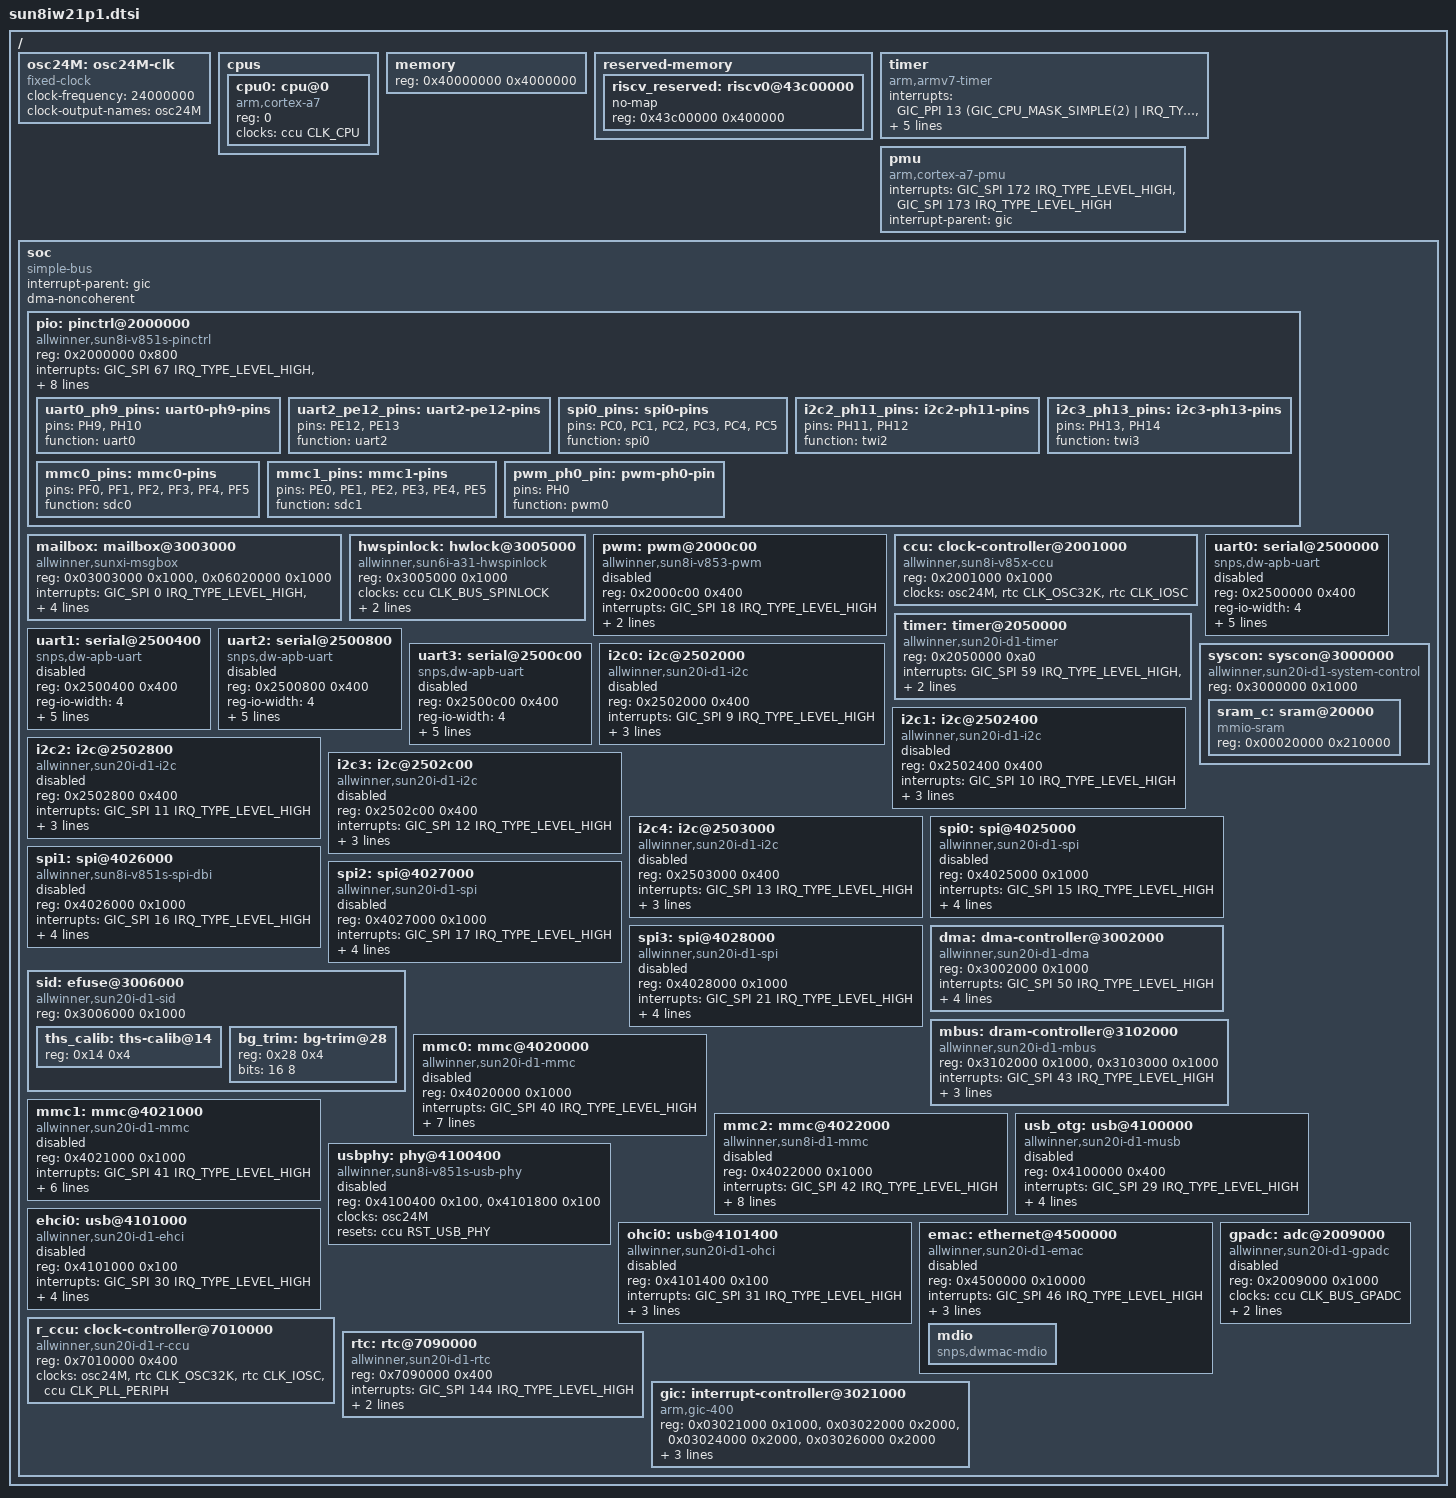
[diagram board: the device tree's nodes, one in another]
// SPDX-License-Identifier: (GPL-2.0+ or MIT)
// Copyright (C) 2021-2022 Samuel Holland <samuel@sholland.org>

#include <dt-bindings/clock/sun6i-rtc.h>
#include <dt-bindings/clock/sun8i-de2.h>
#include <dt-bindings/clock/sun8i-tcon-top.h>
#include <dt-bindings/clock/sun20i-d1-r-ccu.h>
#include <dt-bindings/reset/sun20i-d1-r-ccu.h>
#include <dt-bindings/clock/sun8i-v85x-ccu.h>
#include <dt-bindings/reset/sun8i-v85x-ccu.h>
#include <dt-bindings/interrupt-controller/arm-gic.h>
#include <dt-bindings/reset/sun8i-de2.h>
#include <dt-bindings/thermal/thermal.h>

/ {
	#address-cells = <1>;
	#size-cells = <1>;

	osc24M: osc24M-clk {
		compatible = "fixed-clock";
		clock-frequency = <24000000>;
		clock-output-names = "osc24M";
		#clock-cells = <0>;
	};

	cpus {
			#address-cells = <1>;
			#size-cells = <0>;

			cpu0: cpu@0 {
				device_type = "cpu";
				compatible = "arm,cortex-a7";
				reg = <0>;
				clocks = <&ccu CLK_CPU>;
				clock-names = "cpu";
			};
	};

	memory {
		reg = <0x40000000 0x4000000>;
	};

	reserved-memory {
		#address-cells = <1>;
		#size-cells = <1>;
		ranges;

		riscv_reserved: riscv0@43c00000 {
			no-map;
			reg = <0x43c00000 0x400000>;
		};
	};

	timer {
		compatible = "arm,armv7-timer";
		interrupts = <GIC_PPI 13 (GIC_CPU_MASK_SIMPLE(2) | IRQ_TYPE_LEVEL_LOW)>,
					 <GIC_PPI 14 (GIC_CPU_MASK_SIMPLE(2) | IRQ_TYPE_LEVEL_LOW)>,
					 <GIC_PPI 11 (GIC_CPU_MASK_SIMPLE(2) | IRQ_TYPE_LEVEL_LOW)>,
					 <GIC_PPI 10 (GIC_CPU_MASK_SIMPLE(2) | IRQ_TYPE_LEVEL_LOW)>;
		clock-frequency = <24000000>;
		interrupt-parent = <&gic>;
/*
		arm,cpu-registers-not-fw-configured;
		arm,no-tick-in-suspend;
*/
	};

	pmu {
		compatible = "arm,cortex-a7-pmu";
		interrupts = <GIC_SPI 172 IRQ_TYPE_LEVEL_HIGH>,
					 <GIC_SPI 173 IRQ_TYPE_LEVEL_HIGH>;
		interrupt-parent = <&gic>;
	};

	soc {
		compatible = "simple-bus";
		ranges;
		interrupt-parent = <&gic>;
		#address-cells = <1>;
		#size-cells = <1>;
		dma-noncoherent;

/* A (B) C D E F (G) H */

		pio: pinctrl@2000000 {
			compatible = "allwinner,sun8i-v851s-pinctrl";
			reg = <0x2000000 0x800>;
			interrupts = <GIC_SPI 67 IRQ_TYPE_LEVEL_HIGH>, /* GPIOA */
						 <GIC_SPI 71 IRQ_TYPE_LEVEL_HIGH>, /* GPIOC */
						 <GIC_SPI 73 IRQ_TYPE_LEVEL_HIGH>, /* GPIOD */
						 <GIC_SPI 75 IRQ_TYPE_LEVEL_HIGH>, /* GPIOE */
						 <GIC_SPI 77 IRQ_TYPE_LEVEL_HIGH>, /* GPIOF */
						 <GIC_SPI 81 IRQ_TYPE_LEVEL_HIGH>; /* GPIOH */
			clocks = <&ccu CLK_APB0>, <&osc24M>, <&rtc CLK_OSC32K>;
			clock-names = "apb", "hosc", "losc";
			gpio-controller;
			interrupt-controller;
			#gpio-cells = <3>;
			#interrupt-cells = <3>;

			/omit-if-no-ref/
			uart0_ph9_pins: uart0-ph9-pins {
				pins = "PH9", "PH10";
				function = "uart0";
			};

			/omit-if-no-ref/
			uart2_pe12_pins: uart2-pe12-pins {
				pins = "PE12", "PE13";
				function = "uart2";
			};

			/omit-if-no-ref/
			spi0_pins: spi0-pins {
				pins = "PC0", "PC1", "PC2", "PC3", "PC4", "PC5";
				function = "spi0";
			};

			/omit-if-no-ref/
			i2c2_ph11_pins: i2c2-ph11-pins {
				pins = "PH11", "PH12";
				function = "twi2";
			};

			/omit-if-no-ref/
			i2c3_ph13_pins: i2c3-ph13-pins {
				pins = "PH13", "PH14";
				function = "twi3";
			};

			/omit-if-no-ref/
			mmc0_pins: mmc0-pins {
				pins = "PF0", "PF1", "PF2", "PF3", "PF4", "PF5";
				function = "sdc0";
			};

			/omit-if-no-ref/
			mmc1_pins: mmc1-pins {
				pins = "PE0", "PE1", "PE2", "PE3", "PE4", "PE5";
				function = "sdc1";
			};

			/omit-if-no-ref/
			pwm_ph0_pin: pwm-ph0-pin {
				pins = "PH0";
				function = "pwm0";
			};
		};
/*
		msgbox: mailbox@3003000 {
			compatible = "allwinner,sun8i-h3-msgbox",
						 "allwinner,sun6i-a31-msgbox";
			reg = <0x03003000 0x1000>;
			interrupts = <GIC_SPI 0 IRQ_TYPE_LEVEL_HIGH>;
			clocks = <&ccu CLK_BUS_MSGBOX0>;
			resets = <&ccu RST_BUS_MSGBOX0>;
			#mbox-cells = <1>;
			status = "okay";
		};
*/

		mailbox: mailbox@3003000 {
			compatible = "allwinner,sunxi-msgbox";
			#mbox-cells = <1>;
			reg = <0x03003000 0x1000>,
				  <0x06020000 0x1000>;
			interrupts = <GIC_SPI 0 IRQ_TYPE_LEVEL_HIGH>,
						 <GIC_SPI 1 IRQ_TYPE_LEVEL_HIGH>;
			clocks = <&ccu CLK_BUS_MSGBOX0>;
			clock-names = "msgbox0";
			resets = <&ccu RST_BUS_MSGBOX0>;
			local_id = <0>;
			status = "okay";
		};

		hwspinlock: hwlock@3005000 {
		    compatible = "allwinner,sun6i-a31-hwspinlock";
			reg = <0x3005000 0x1000>;
			clocks = <&ccu CLK_BUS_SPINLOCK>;
			clock-names = "ahb";
			resets = <&ccu RST_BUS_SPINLOCK>;
			reset-names = "ahb";
			interrupts = <GIC_SPI 54 IRQ_TYPE_LEVEL_HIGH>;
		};

		pwm: pwm@2000c00 {
			compatible = "allwinner,sun8i-v853-pwm";
			reg = <0x2000c00 0x400>;
			interrupts = <GIC_SPI 18 IRQ_TYPE_LEVEL_HIGH>;
			clocks = <&ccu CLK_BUS_PWM>, <&osc24M>;
			clock-names = "bus", "mod";
			resets = <&ccu RST_BUS_PWM>;
			status = "disabled";
			#pwm-cells = <3>;
		};

		ccu: clock-controller@2001000 {
			compatible = "allwinner,sun8i-v85x-ccu";
			reg = <0x2001000 0x1000>;
			clocks = <&osc24M>,
				<&rtc CLK_OSC32K>,
				<&rtc CLK_IOSC>;
			clock-names = "hosc", "losc", "iosc";
			#clock-cells = <1>;
			#reset-cells = <1>;
		};


		timer: timer@2050000 {
			compatible = "allwinner,sun20i-d1-timer",
						 "allwinner,sun8i-a23-timer";
			reg = <0x2050000 0xa0>;
			interrupts = <GIC_SPI 59 IRQ_TYPE_LEVEL_HIGH>,
						 <GIC_SPI 60 IRQ_TYPE_LEVEL_HIGH>;
			clocks = <&osc24M>;
		};

		uart0: serial@2500000 {
			compatible = "snps,dw-apb-uart";
			reg = <0x2500000 0x400>;
			reg-io-width = <4>;
			reg-shift = <2>;
			interrupts = <GIC_SPI 2 IRQ_TYPE_LEVEL_HIGH>;
			clocks = <&ccu CLK_BUS_UART0>;
			resets = <&ccu RST_BUS_UART0>;
			dmas = <&dma 14>, <&dma 14>;
			dma-names = "rx", "tx";
			status = "disabled";
		};

		uart1: serial@2500400 {
			compatible = "snps,dw-apb-uart";
			reg = <0x2500400 0x400>;
			reg-io-width = <4>;
			reg-shift = <2>;
			interrupts = <GIC_SPI 3 IRQ_TYPE_LEVEL_HIGH>;
			clocks = <&ccu CLK_BUS_UART1>;
			resets = <&ccu RST_BUS_UART1>;
			dmas = <&dma 15>, <&dma 15>;
			dma-names = "rx", "tx";
			status = "disabled";
		};

		uart2: serial@2500800 {
			compatible = "snps,dw-apb-uart";
			reg = <0x2500800 0x400>;
			reg-io-width = <4>;
			reg-shift = <2>;
			interrupts = <GIC_SPI 4 IRQ_TYPE_LEVEL_HIGH>;
			clocks = <&ccu CLK_BUS_UART2>;
			resets = <&ccu RST_BUS_UART2>;
			dmas = <&dma 16>, <&dma 16>;
			dma-names = "rx", "tx";
			status = "disabled";
		};

		uart3: serial@2500c00 {
			compatible = "snps,dw-apb-uart";
			reg = <0x2500c00 0x400>;
			reg-io-width = <4>;
			reg-shift = <2>;
			interrupts = <GIC_SPI 5 IRQ_TYPE_LEVEL_HIGH>;
			clocks = <&ccu CLK_BUS_UART3>;
			resets = <&ccu RST_BUS_UART3>;
			dmas = <&dma 17>, <&dma 17>;
			dma-names = "rx", "tx";
			status = "disabled";
		};

		i2c0: i2c@2502000 {
			compatible = "allwinner,sun20i-d1-i2c",
				     "allwinner,sun8i-v536-i2c",
				     "allwinner,sun6i-a31-i2c";
			reg = <0x2502000 0x400>;
			interrupts = <GIC_SPI 9 IRQ_TYPE_LEVEL_HIGH>;
			clocks = <&ccu CLK_BUS_I2C0>;
			resets = <&ccu RST_BUS_I2C0>;
			dmas = <&dma 43>, <&dma 43>;
			dma-names = "rx", "tx";
			status = "disabled";
			#address-cells = <1>;
			#size-cells = <0>;
		};

		i2c1: i2c@2502400 {
			compatible = "allwinner,sun20i-d1-i2c",
						 "allwinner,sun8i-v536-i2c",
						 "allwinner,sun6i-a31-i2c";
			reg = <0x2502400 0x400>;
			interrupts = <GIC_SPI 10 IRQ_TYPE_LEVEL_HIGH>;
			clocks = <&ccu CLK_BUS_I2C1>;
			resets = <&ccu RST_BUS_I2C1>;
			dmas = <&dma 44>, <&dma 44>;
			dma-names = "rx", "tx";
			status = "disabled";
			#address-cells = <1>;
			#size-cells = <0>;
		};

		i2c2: i2c@2502800 {
			compatible = "allwinner,sun20i-d1-i2c",
						 "allwinner,sun8i-v536-i2c",
						 "allwinner,sun6i-a31-i2c";
			reg = <0x2502800 0x400>;
			interrupts = <GIC_SPI 11 IRQ_TYPE_LEVEL_HIGH>;
			clocks = <&ccu CLK_BUS_I2C2>;
			resets = <&ccu RST_BUS_I2C2>;
			dmas = <&dma 45>, <&dma 45>;
			dma-names = "rx", "tx";
			status = "disabled";
			#address-cells = <1>;
			#size-cells = <0>;
		};

		i2c3: i2c@2502c00 {
			compatible = "allwinner,sun20i-d1-i2c",
						 "allwinner,sun8i-v536-i2c",
						 "allwinner,sun6i-a31-i2c";
			reg = <0x2502c00 0x400>;
			interrupts = <GIC_SPI 12 IRQ_TYPE_LEVEL_HIGH>;
			clocks = <&ccu CLK_BUS_I2C3>;
			resets = <&ccu RST_BUS_I2C3>;
			dmas = <&dma 46>, <&dma 46>;
			dma-names = "rx", "tx";
			status = "disabled";
			#address-cells = <1>;
			#size-cells = <0>;
		};


		i2c4: i2c@2503000 {
			compatible = "allwinner,sun20i-d1-i2c",
						 "allwinner,sun8i-v536-i2c",
						 "allwinner,sun6i-a31-i2c";
			reg = <0x2503000 0x400>;
			interrupts = <GIC_SPI 13 IRQ_TYPE_LEVEL_HIGH>;
			clocks = <&ccu CLK_BUS_I2C4>;
			resets = <&ccu RST_BUS_I2C4>;
			dmas = <&dma 47>, <&dma 47>;
			dma-names = "rx", "tx";
			status = "disabled";
			#address-cells = <1>;
			#size-cells = <0>;
		};

		syscon: syscon@3000000 {
			compatible = "allwinner,sun20i-d1-system-control";
			reg = <0x3000000 0x1000>;
			ranges;
			#address-cells = <1>;
			#size-cells = <1>;

			sram_c: sram@20000 {
				compatible = "mmio-sram";
				reg = <0x00020000 0x210000>;
				#address-cells = <1>;
				#size-cells = <1>;
				ranges = <0 0x00020000 0x21000>;
			};
		};

		spi0: spi@4025000 {
			compatible = "allwinner,sun20i-d1-spi",
						 "allwinner,sun50i-r329-spi";
			reg = <0x4025000 0x1000>;
			interrupts = <GIC_SPI 15 IRQ_TYPE_LEVEL_HIGH>;
			clocks = <&ccu CLK_BUS_SPI0>, <&ccu CLK_SPI0>;
			clock-names = "ahb", "mod";
			resets = <&ccu RST_BUS_SPI0>;
			dmas = <&dma 22>, <&dma 22>;
			dma-names = "rx", "tx";
			num-cs = <1>;
			status = "disabled";
			#address-cells = <1>;
			#size-cells = <0>;
		};

		spi1: spi@4026000 {
			compatible = "allwinner,sun8i-v851s-spi-dbi",
						 "allwinner,sun50i-r329-spi-dbi",
						 "allwinner,sun50i-r329-spi";
			reg = <0x4026000 0x1000>;
			interrupts = <GIC_SPI 16 IRQ_TYPE_LEVEL_HIGH>;
			clocks = <&ccu CLK_BUS_SPI1>, <&ccu CLK_SPI1>;
			clock-names = "ahb", "mod";
			resets = <&ccu RST_BUS_SPI1>;
			dmas = <&dma 23>, <&dma 23>;
			dma-names = "rx", "tx";
			num-cs = <1>;
			status = "disabled";
			#address-cells = <1>;
			#size-cells = <0>;
		};

		spi2: spi@4027000 {
			compatible = "allwinner,sun20i-d1-spi",
						 "allwinner,sun50i-r329-spi";
			reg = <0x4027000 0x1000>;
			interrupts = <GIC_SPI 17 IRQ_TYPE_LEVEL_HIGH>;
			clocks = <&ccu CLK_BUS_SPI2>, <&ccu CLK_SPI2>;
			clock-names = "ahb", "mod";
			resets = <&ccu RST_BUS_SPI2>;
			dmas = <&dma 24>, <&dma 24>;
			dma-names = "rx", "tx";
			num-cs = <1>;
			status = "disabled";
			#address-cells = <1>;
			#size-cells = <0>;
		};

		spi3: spi@4028000 {
			compatible = "allwinner,sun20i-d1-spi",
						 "allwinner,sun50i-r329-spi";
			reg = <0x4028000 0x1000>;
			interrupts = <GIC_SPI 21 IRQ_TYPE_LEVEL_HIGH>;
			clocks = <&ccu CLK_BUS_SPI3>, <&ccu CLK_SPI3>;
			clock-names = "ahb", "mod";
			resets = <&ccu RST_BUS_SPI3>;
			dmas = <&dma 25>, <&dma 25>;
			dma-names = "rx", "tx";
			num-cs = <1>;
			status = "disabled";
			#address-cells = <1>;
			#size-cells = <0>;
		};
/*
		syscon: syscon@3000000 {
			compatible = "allwinner,sun20i-d1-system-control";
			reg = <0x3000000 0x1000>;
			ranges;
			#address-cells = <1>;
			#size-cells = <1>;

			regulators@3000150 {
				compatible = "allwinner,sun20i-d1-system-ldos";
				reg = <0x3000150 0x4>;

				reg_ldoa: ldoa {
				};

				reg_ldob: ldob {
				};
			};

			sram_c: sram@20000 {
				compatible = "mmio-sram";
				reg = <0x00020000 0x21000>;
				#address-cells = <1>;
				#size-cells = <1>;
				ranges = <0 0x00020000 0x21000>;

				ve_sram: sram-section@0 {
					compatible = "allwinner,sun20i-d1-sram-c1",
								 "allwinner,sun4i-a10-sram-c1";
					reg = <0x000000 0x21000>;
				};
			};
		};
*/

		dma: dma-controller@3002000 {
			compatible = "allwinner,sun20i-d1-dma";
			reg = <0x3002000 0x1000>;
			interrupts = <GIC_SPI 50 IRQ_TYPE_LEVEL_HIGH>;
			clocks = <&ccu CLK_BUS_DMA>, <&ccu CLK_MBUS_DMA>;
			clock-names = "bus", "mbus";
			resets = <&ccu RST_BUS_DMA>;
			dma-channels = <16>;
			dma-requests = <64>;
			#dma-cells = <1>;
		};

		sid: efuse@3006000 {
			compatible = "allwinner,sun20i-d1-sid";
			reg = <0x3006000 0x1000>;
			#address-cells = <1>;
			#size-cells = <1>;

			ths_calib: ths-calib@14 {
				reg = <0x14 0x4>;
			};

			bg_trim: bg-trim@28 {
				reg = <0x28 0x4>;
				bits = <16 8>;
			};
		};

		mbus: dram-controller@3102000 {
			compatible = "allwinner,sun20i-d1-mbus";
			reg = <0x3102000 0x1000>,
				  <0x3103000 0x1000>;
			reg-names = "mbus", "dram";
			interrupts = <GIC_SPI 43 IRQ_TYPE_LEVEL_HIGH>;
			clocks = <&ccu CLK_MBUS>,
				 <&ccu CLK_DRAM>,
				 <&ccu CLK_BUS_DRAM>;
			clock-names = "mbus", "dram", "bus";
			dma-ranges = <0 0x40000000 0x80000000>;
			#address-cells = <1>;
			#size-cells = <1>;
			#interconnect-cells = <1>;
		};


		mmc0: mmc@4020000 {
			compatible = "allwinner,sun20i-d1-mmc";
			reg = <0x4020000 0x1000>;
			interrupts = <GIC_SPI 40 IRQ_TYPE_LEVEL_HIGH>;
			clocks = <&ccu CLK_BUS_MMC0>, <&ccu CLK_MMC0>;
			clock-names = "ahb", "mmc";
			resets = <&ccu RST_BUS_MMC0>;
			reset-names = "ahb";
			no-sdio;
			no-mmc;
			cap-sd-highspeed;
			max-frequency = <150000000>;
			mmc-ddr-1_8v;
			status = "disabled";
			#address-cells = <1>;
			#size-cells = <0>;
		};

		mmc1: mmc@4021000 {
			compatible = "allwinner,sun20i-d1-mmc";
			reg = <0x4021000 0x1000>;
			interrupts = <GIC_SPI 41 IRQ_TYPE_LEVEL_HIGH>;
			clocks = <&ccu CLK_BUS_MMC1>, <&ccu CLK_MMC1>;
			clock-names = "ahb", "mmc";
			resets = <&ccu RST_BUS_MMC1>;
			reset-names = "ahb";
			cap-sd-highspeed;
			cap-mmc-highspeed;
			max-frequency = <150000000>;
			mmc-ddr-1_8v;
			status = "disabled";
			#address-cells = <1>;
			#size-cells = <0>;
		};

		mmc2: mmc@4022000 {
			compatible = "allwinner,sun8i-d1-mmc";
			reg = <0x4022000 0x1000>;
			interrupts = <GIC_SPI 42 IRQ_TYPE_LEVEL_HIGH>;
			clocks = <&ccu CLK_BUS_MMC2>, <&ccu CLK_MMC2>;
			clock-names = "ahb", "mmc";
			resets = <&ccu RST_BUS_MMC2>;
			reset-names = "ahb";
			no-sdio;
			no-sd;
			cap-mmc-highspeed;
			max-frequency = <150000000>;
			mmc-ddr-1_8v;
			mmc-ddr-3_3v;
			status = "disabled";
			#address-cells = <1>;
			#size-cells = <0>;
		};

		usb_otg: usb@4100000 {
			compatible = "allwinner,sun20i-d1-musb",
						 "allwinner,sun8i-a33-musb";
			reg = <0x4100000 0x400>;
			interrupts = <GIC_SPI 29 IRQ_TYPE_LEVEL_HIGH>;
			interrupt-names = "mc";
			clocks = <&ccu CLK_BUS_OTG>;
			resets = <&ccu RST_BUS_OTG>;
			extcon = <&usbphy 0>;
			phys = <&usbphy 0>;
			phy-names = "usb";
			status = "disabled";
		};

		usbphy: phy@4100400 {
			compatible = "allwinner,sun8i-v851s-usb-phy";
			reg = <0x4100400 0x100>,
				  <0x4101800 0x100>;
			reg-names = "phy_ctrl",
						"pmu0";
			clocks = <&osc24M>;
			clock-names = "usb0_phy";
			resets = <&ccu RST_USB_PHY>;
			reset-names = "usb0_reset";
			status = "disabled";
			#phy-cells = <1>;
		};

		ehci0: usb@4101000 {
			compatible = "allwinner,sun20i-d1-ehci",
						 "generic-ehci";
			reg = <0x4101000 0x100>;
			interrupts = <GIC_SPI 30 IRQ_TYPE_LEVEL_HIGH>;
			clocks = <&ccu CLK_BUS_OHCI>,
				 <&ccu CLK_BUS_EHCI>,
				 <&ccu CLK_USB_OHCI>;
			resets = <&ccu RST_BUS_OHCI>,
				 <&ccu RST_BUS_EHCI>;
			phys = <&usbphy 0>;
			phy-names = "usb";
			status = "disabled";
		};

		ohci0: usb@4101400 {
			compatible = "allwinner,sun20i-d1-ohci",
						 "generic-ohci";
			reg = <0x4101400 0x100>;
			interrupts = <GIC_SPI 31 IRQ_TYPE_LEVEL_HIGH>;
			clocks = <&ccu CLK_BUS_OHCI>,
				 <&ccu CLK_USB_OHCI>;
			resets = <&ccu RST_BUS_OHCI>;
			phys = <&usbphy 0>;
			phy-names = "usb";
			status = "disabled";
		};

		emac: ethernet@4500000 {
			compatible = "allwinner,sun20i-d1-emac",
						 "allwinner,sun50i-a64-emac";
			reg = <0x4500000 0x10000>;
			interrupts = <GIC_SPI 46 IRQ_TYPE_LEVEL_HIGH>;
			interrupt-names = "macirq";
			clocks = <&ccu CLK_BUS_EMAC>;
			clock-names = "stmmaceth";
			resets = <&ccu RST_BUS_EMAC>;
			reset-names = "stmmaceth";
			syscon = <&syscon>;
			status = "disabled";

			mdio: mdio {
				compatible = "snps,dwmac-mdio";
				#address-cells = <1>;
				#size-cells = <0>;
			};
		};

		r_ccu: clock-controller@7010000 {
			compatible = "allwinner,sun20i-d1-r-ccu";
			reg = <0x7010000 0x400>;
			clocks = <&osc24M>,
				 <&rtc CLK_OSC32K>,
				 <&rtc CLK_IOSC>,
/*				 <&ccu CLK_PLL_PERIPH0_DIV3>; */
				 <&ccu CLK_PLL_PERIPH>;
			clock-names = "hosc", "losc", "iosc", "pll-periph";
			#clock-cells = <1>;
			#reset-cells = <1>;
		};

		rtc: rtc@7090000 {
			compatible = "allwinner,sun20i-d1-rtc",
						 "allwinner,sun50i-r329-rtc";
			reg = <0x7090000 0x400>;
			interrupts = <GIC_SPI 144 IRQ_TYPE_LEVEL_HIGH>;
			clocks = <&r_ccu CLK_BUS_R_RTC>,
				 <&osc24M>,
				 <&r_ccu CLK_R_AHB>;
			clock-names = "bus", "hosc", "ahb";
			#clock-cells = <1>;
		};

		gic: interrupt-controller@3021000 {
			compatible = "arm,gic-400";
			reg = <0x03021000 0x1000>,
				  <0x03022000 0x2000>,
				  <0x03024000 0x2000>,
				  <0x03026000 0x2000>;
				  interrupts = <GIC_PPI 9 (GIC_CPU_MASK_SIMPLE(2) | IRQ_TYPE_LEVEL_HIGH)>;
				  interrupt-controller;
				  #interrupt-cells = <3>;
		};
/*
		iommu: iommu@2010000 {
			compatible = "allwinner,sun50i-h6-iommu";
			reg = <0x02010000 0x10000>;
			interrupts = <GIC_SPI 64 IRQ_TYPE_LEVEL_HIGH>;
			clocks = <&ccu CLK_BUS_IOMMU>;
			resets = <&ccu RST_BUS_IOMMU>;
			#iommu-cells = <1>;
		};

		iommus = <&iommu 5>;
*/

		gpadc: adc@2009000 {
			compatible = "allwinner,sun20i-d1-gpadc";
			reg = <0x2009000 0x1000>;
			clocks = <&ccu CLK_BUS_GPADC>;
			resets = <&ccu RST_BUS_GPADC>;
			interrupts = <GIC_SPI 57 IRQ_TYPE_LEVEL_HIGH>;
			status = "disabled";
			#io-channel-cells = <1>;
		};

	};
};
